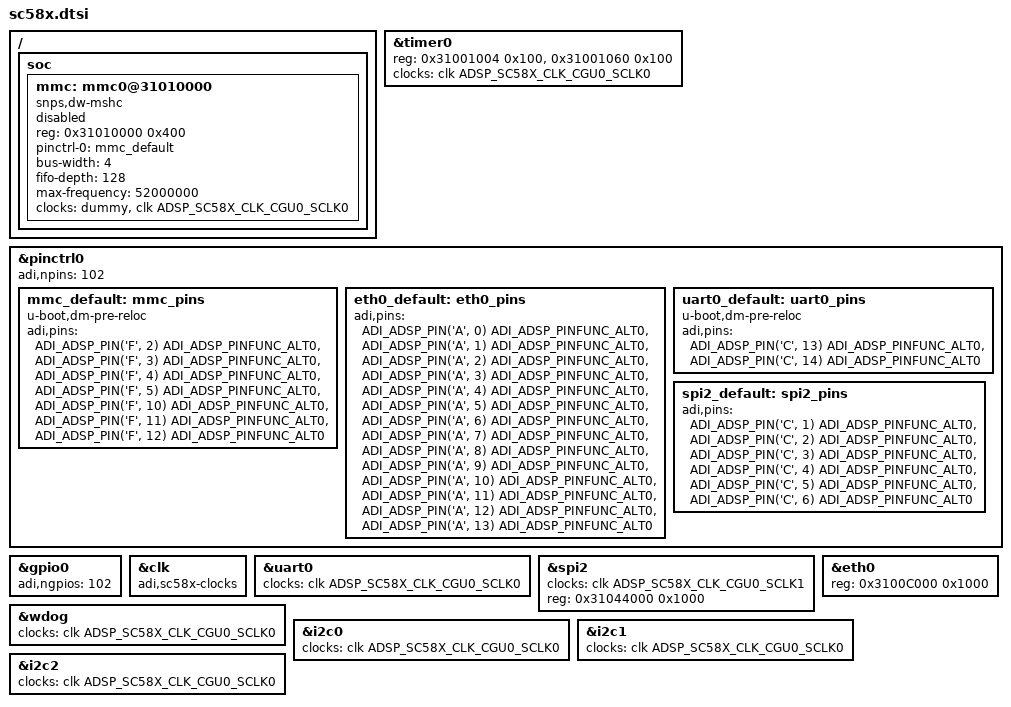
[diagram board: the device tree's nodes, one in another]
/ {
	soc {
		mmc: mmc0@31010000 {
			compatible = "snps,dw-mshc";
			reg = <0x31010000 0x400>;
			pinctrl-names = "default";
			pinctrl-0 = <&mmc_default>;
			bus-width = <4>;
			fifo-depth = <128>;
			clock-names = "biu", "ciu";
			max-frequency = <52000000>;
			status = "disabled";
		};
	};
};

&timer0 {
	reg = <0x31001004 0x100>,
	      <0x31001060 0x100>;
	clocks = <&clk ADSP_SC58X_CLK_CGU0_SCLK0>;
};

&pinctrl0 {
	mmc_default: mmc_pins {
		u-boot,dm-pre-reloc;
	    adi,pins = <ADI_ADSP_PIN('F', 2) ADI_ADSP_PINFUNC_ALT0>,
	               <ADI_ADSP_PIN('F', 3) ADI_ADSP_PINFUNC_ALT0>,
	               <ADI_ADSP_PIN('F', 4) ADI_ADSP_PINFUNC_ALT0>,
	               <ADI_ADSP_PIN('F', 5) ADI_ADSP_PINFUNC_ALT0>,
			       <ADI_ADSP_PIN('F', 10) ADI_ADSP_PINFUNC_ALT0>,
			       <ADI_ADSP_PIN('F', 11) ADI_ADSP_PINFUNC_ALT0>,
			       <ADI_ADSP_PIN('F', 12) ADI_ADSP_PINFUNC_ALT0>;
	};

	eth0_default: eth0_pins {
		adi,pins = <ADI_ADSP_PIN('A', 0) ADI_ADSP_PINFUNC_ALT0>,
	               <ADI_ADSP_PIN('A', 1) ADI_ADSP_PINFUNC_ALT0>,
	               <ADI_ADSP_PIN('A', 2) ADI_ADSP_PINFUNC_ALT0>,
	               <ADI_ADSP_PIN('A', 3) ADI_ADSP_PINFUNC_ALT0>,
	               <ADI_ADSP_PIN('A', 4) ADI_ADSP_PINFUNC_ALT0>,
	               <ADI_ADSP_PIN('A', 5) ADI_ADSP_PINFUNC_ALT0>,
	               <ADI_ADSP_PIN('A', 6) ADI_ADSP_PINFUNC_ALT0>,
	               <ADI_ADSP_PIN('A', 7) ADI_ADSP_PINFUNC_ALT0>,
	               <ADI_ADSP_PIN('A', 8) ADI_ADSP_PINFUNC_ALT0>,
	               <ADI_ADSP_PIN('A', 9) ADI_ADSP_PINFUNC_ALT0>,
	               <ADI_ADSP_PIN('A', 10) ADI_ADSP_PINFUNC_ALT0>,
	               <ADI_ADSP_PIN('A', 11) ADI_ADSP_PINFUNC_ALT0>,
	               <ADI_ADSP_PIN('A', 12) ADI_ADSP_PINFUNC_ALT0>,
	               <ADI_ADSP_PIN('A', 13) ADI_ADSP_PINFUNC_ALT0>;
	};

	uart0_default: uart0_pins {
		u-boot,dm-pre-reloc;
		adi,pins = <ADI_ADSP_PIN('C', 13) ADI_ADSP_PINFUNC_ALT0>,
		           <ADI_ADSP_PIN('C', 14) ADI_ADSP_PINFUNC_ALT0>;
	};

	spi2_default: spi2_pins {
		adi,pins = <ADI_ADSP_PIN('C', 1) ADI_ADSP_PINFUNC_ALT0>,
				   <ADI_ADSP_PIN('C', 2) ADI_ADSP_PINFUNC_ALT0>,
				   <ADI_ADSP_PIN('C', 3) ADI_ADSP_PINFUNC_ALT0>,
				   <ADI_ADSP_PIN('C', 4) ADI_ADSP_PINFUNC_ALT0>,
				   <ADI_ADSP_PIN('C', 5) ADI_ADSP_PINFUNC_ALT0>,
				   <ADI_ADSP_PIN('C', 6) ADI_ADSP_PINFUNC_ALT0>;
	};
};

&pinctrl0 {
	adi,npins = <102>;
};

&gpio0 {
	adi,ngpios = <102>;
};

&clk{
	compatible = "adi,sc58x-clocks";
};

&uart0{
	clocks = <&clk ADSP_SC58X_CLK_CGU0_SCLK0>;
};

&spi2{
	clocks = <&clk ADSP_SC58X_CLK_CGU0_SCLK1>;
	reg = <0x31044000 0x1000>;
};

&wdog{
	clocks = <&clk ADSP_SC58X_CLK_CGU0_SCLK0>;
};

&eth0{
	reg = <0x3100C000 0x1000>;
};

&mmc{
	clocks = <&dummy>, <&clk ADSP_SC58X_CLK_CGU0_SCLK0>;
};

&i2c0{
	clocks = <&clk ADSP_SC58X_CLK_CGU0_SCLK0>;
};

&i2c1{
	clocks = <&clk ADSP_SC58X_CLK_CGU0_SCLK0>;
};

&i2c2{
	clocks = <&clk ADSP_SC58X_CLK_CGU0_SCLK0>;
};
